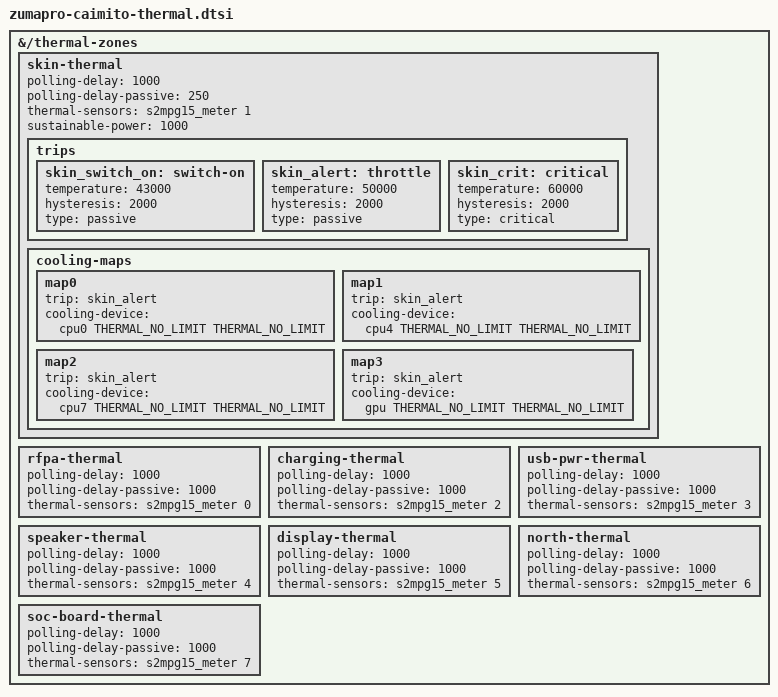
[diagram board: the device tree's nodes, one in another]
// SPDX-License-Identifier: GPL-2.0-only
/*
 * Thermistors for the caimito boards -- caiman, komodo and tokay.
 *
 * The S2MPG15's meter block drives eight NTC channels, and which thermistor
 * sits on which channel is a property of the board rather than of the SoC:
 * channel 1 is skin here, the RF front end on comet and a modem die sensor on
 * tegu. So this belongs per-board, and these assignments are caimito's.
 *
 * Only the skin zone throttles anything. The rest are here to be read: the
 * vendor hands every one of them to its userspace thermal HAL ("user_space"
 * governor, polling disabled) and keeps no policy for them in its device
 * tree, so there is nothing to copy, and inventing trips for a sensor whose
 * safe range nobody has stated would be guesswork. Declaring them still costs
 * little and makes them measurable -- the driver enables exactly the channels
 * named here -- which matters because they answer what the die sensors cannot,
 * display-thermal most of all.
 *
 * Copyright 2026 Trijal Saha - <trijalsaha2012@gmail.com>
 */

#include <dt-bindings/thermal/thermal.h>

&{/thermal-zones} {
	/*
	 * The skin zone, on the thermistor next to the case rather than a sensor
	 * inside the SoC. This is the one the vendor stack regulates on, and the
	 * reason it can run the silicon hotter than a die-temperature policy dares
	 * to: a die reading cannot tell a brief spike on a cold phone from sustained
	 * load on a hot one, so it has to assume the worst and throttle early.
	 *
	 * The die zones in zumapro.dtsi stay as they are. They protect the silicon,
	 * locally and quickly; this protects the user, globally and slowly. Where
	 * both name the same cooling device the thermal core takes the higher
	 * requested state, so the stricter of the two wins.
	 *
	 * Unlike those zones, this one budgets all four cooling devices together,
	 * which is what a skin measurement actually constrains -- total board power,
	 * however it is being spent.
	 */
	skin-thermal {
		/* Skin temperature moves in seconds, not milliseconds. */
		polling-delay = <1000>;
		polling-delay-passive = <250>;
		thermal-sensors = <&s2mpg15_meter 1>;	/* quiet_therm */

		/*
		 * Both numbers below are the tuning knobs, and neither came
		 * from the vendor: its kernel delegates this zone to userspace
		 * ("user_space" governor, polling disabled) and the real
		 * control points live in the Android thermal HAL's config, not
		 * in its device tree. What its DT does say is where it gives
		 * up -- 56 C notify, 60 C shutdown, 65 C hardware shutdown --
		 * so the safe operating range sits well below those.
		 *
		 * The switch-on has to sit above the temperature the phone
		 * actually idles at, or the reset never fires and the integral
		 * can stay latched -- see the trips below. This board idles at
		 * 41-42 C skin with a compositor running, measured, so 43 C is
		 * the floor for it, and the control point has to be far enough
		 * above that for the derived gains to stay sane: a 45 C target
		 * would leave a 2 C band and a near-relay k_po of 1280.
		 *
		 * 50 C is therefore a consequence of this board idling warm,
		 * not a judgement that 50 C is a pleasant thing to hold. It
		 * sits under the vendor's own 56 C notify point. The honest fix
		 * is the idle temperature itself -- a phone with nothing to do
		 * should be nearer 33 C than 42 C -- and that is a separate
		 * problem: the panel runs at 120 Hz regardless, the GPU keeps
		 * its clocks up, and there is no cluster or system idle state.
		 * Lower this once those land.
		 */
		/*
		 * This also sets the controller's gains, which is the reason it is
		 * not simply the board's measured dissipation: the governor derives
		 * k_po = sustainable_power / (control - switch_on), k_pu = 2 * k_po
		 * and k_i = k_pu / 10, and nothing else in the device tree can
		 * reach them. At 2500 the integral gain came out 15 times the
		 * vendor's, and the allocation visibly relaxed and saturated every
		 * few seconds -- the big core swinging between 700MHz and its
		 * ceiling while the skin sat a degree under the control point.
		 *
		 * 1000 puts k_pu within a few percent of the 300 the vendor uses
		 * for the same set of actors and cuts the integral gain to a third.
		 * Its own k_i is 5, which this cannot reach from here.
		 */
		sustainable-power = <1000>;

		trips {
			/*
			 * The lower of two passive trips is IPA's switch-on
			 * point, and it is not optional. Below it the governor
			 * calls reset_pid_controller() and allow_maximum_power()
			 * and gets out of the way; with a single passive trip
			 * get_governor_trips() leaves trip_switch_on NULL, that
			 * branch never runs, and the governor controls at every
			 * temperature.
			 *
			 * That is how this zone first shipped, and the failure
			 * is worse than permanent mild control: integral_cutoff
			 * defaults to 0, so the integral term accumulates only
			 * while err < 0 -- above the control temperature. Once a
			 * warm spell winds it negative nothing unwinds it, the
			 * power budget stays clamped to zero, and every actor
			 * sits at its maximum cooling state for good. Measured:
			 * cpu0 pinned to 820 MHz, cpu4 to 357, cpu7 to 700 and
			 * the GPU to its floor, at 42 C against a 45 C
			 * set point, until the zone was disabled.
			 *
			 * The die zones in zumapro.dtsi have the same shape and
			 * the same latent problem; they get away with it only by
			 * sitting ~20 C below their set point, where the
			 * proportional term swamps the integral.
			 *
			 * No cooling map here: IPA allocates across the
			 * instances bound to the control trip below.
			 */
			skin_switch_on: switch-on {
				temperature = <43000>;
				hysteresis = <2000>;
				type = "passive";
			};

			skin_alert: throttle {
				temperature = <50000>;
				hysteresis = <2000>;
				type = "passive";
			};

			/* Mirrors the vendor's backup-shutdown-sw. */
			skin_crit: critical {
				temperature = <60000>;
				hysteresis = <2000>;
				type = "critical";
			};
		};

		cooling-maps {
			map0 {
				trip = <&skin_alert>;
				cooling-device = <&cpu0 THERMAL_NO_LIMIT
						  THERMAL_NO_LIMIT>;
			};

			map1 {
				trip = <&skin_alert>;
				cooling-device = <&cpu4 THERMAL_NO_LIMIT
						  THERMAL_NO_LIMIT>;
			};

			map2 {
				trip = <&skin_alert>;
				cooling-device = <&cpu7 THERMAL_NO_LIMIT
						  THERMAL_NO_LIMIT>;
			};

			map3 {
				trip = <&skin_alert>;
				cooling-device = <&gpu THERMAL_NO_LIMIT
						  THERMAL_NO_LIMIT>;
			};
		};
	};

	/* RF power amplifier */
	rfpa-thermal {
		polling-delay = <1000>;
		polling-delay-passive = <1000>;
		thermal-sensors = <&s2mpg15_meter 0>;
	};

	/* charge path */
	charging-thermal {
		polling-delay = <1000>;
		polling-delay-passive = <1000>;
		thermal-sensors = <&s2mpg15_meter 2>;
	};

	/* USB connector power path */
	usb-pwr-thermal {
		polling-delay = <1000>;
		polling-delay-passive = <1000>;
		thermal-sensors = <&s2mpg15_meter 3>;
	};

	/* bottom speaker */
	speaker-thermal {
		polling-delay = <1000>;
		polling-delay-passive = <1000>;
		thermal-sensors = <&s2mpg15_meter 4>;
	};

	/* display panel */
	display-thermal {
		polling-delay = <1000>;
		polling-delay-passive = <1000>;
		thermal-sensors = <&s2mpg15_meter 5>;
	};

	/* top of the board, by the camera bar */
	north-thermal {
		polling-delay = <1000>;
		polling-delay-passive = <1000>;
		thermal-sensors = <&s2mpg15_meter 6>;
	};

	/* board beside the SoC; not a die sensor */
	soc-board-thermal {
		polling-delay = <1000>;
		polling-delay-passive = <1000>;
		thermal-sensors = <&s2mpg15_meter 7>;
	};
};
